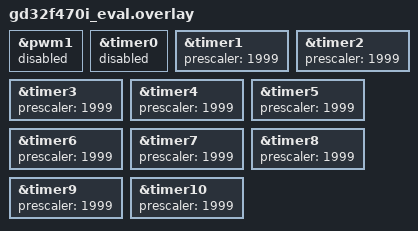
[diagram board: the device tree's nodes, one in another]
/*
 * SPDX-License-Identifier: Apache-2.0
 *
 * Copyright (c) 2022 TOKITA Hiroshi <tokita.hiroshi@fujitsu.com>
 */

&pwm1 {
	status = "disabled";
};

&timer0 {
	status = "disabled";
};

&timer1 {
	prescaler = <1999>;
	status = "okay";
};

&timer2 {
	prescaler = <1999>;
	status = "okay";
};

&timer3 {
	prescaler = <1999>;
	status = "okay";
};

&timer4 {
	prescaler = <1999>;
	status = "okay";
};

&timer5 {
	prescaler = <1999>;
	status = "okay";
};

&timer6 {
	prescaler = <1999>;
	status = "okay";
};

&timer7 {
	prescaler = <1999>;
	status = "okay";
};

&timer8 {
	prescaler = <1999>;
	status = "okay";
};

&timer9 {
	prescaler = <1999>;
	status = "okay";
};

&timer10 {
	prescaler = <1999>;
	status = "okay";
};
